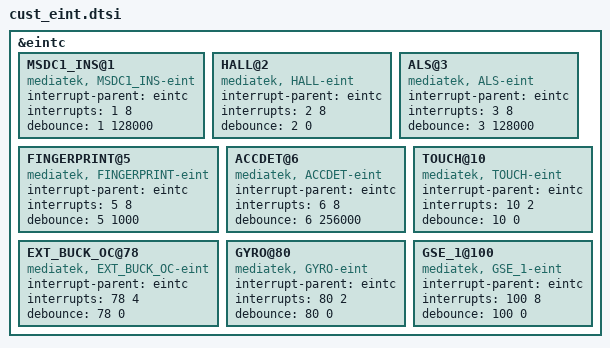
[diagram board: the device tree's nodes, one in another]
/*
 * Generated by MTK SP DrvGen Version 03.13.6 for MT6735M. Copyright MediaTek Inc. (C) 2013.
 * Tue Sep 27 09:54:59 2016
 * Do Not Modify the File.
 */

/*************************
 * EINT DTSI File
*************************/

&eintc {
	MSDC1_INS@1 {
		compatible = "mediatek, MSDC1_INS-eint";
		interrupt-parent = <&eintc>;
		interrupts = <1 8>;
		debounce = <1 128000>;
	};

	HALL@2 {
		compatible = "mediatek, HALL-eint";
		interrupt-parent = <&eintc>;
		interrupts = <2 8>;
		debounce = <2 0>;
	};

	ALS@3 {
		compatible = "mediatek, ALS-eint";
		interrupt-parent = <&eintc>;
		interrupts = <3 8>;
		debounce = <3 128000>;
	};

	FINGERPRINT@5 {
		compatible = "mediatek, FINGERPRINT-eint";
		interrupt-parent = <&eintc>;
		interrupts = <5 8>;
		debounce = <5 1000>;
	};

	ACCDET@6 {
		compatible = "mediatek, ACCDET-eint";
		interrupt-parent = <&eintc>;
		interrupts = <6 8>;
		debounce = <6 256000>;
	};

	TOUCH@10 {
		compatible = "mediatek, TOUCH-eint";
		interrupt-parent = <&eintc>;
		interrupts = <10 2>;
		debounce = <10 0>;
	};

	EXT_BUCK_OC@78 {
		compatible = "mediatek, EXT_BUCK_OC-eint";
		interrupt-parent = <&eintc>;
		interrupts = <78 4>;
		debounce = <78 0>;
	};

	GYRO@80 {
		compatible = "mediatek, GYRO-eint";
		interrupt-parent = <&eintc>;
		interrupts = <80 2>;
		debounce = <80 0>;
	};

	GSE_1@100 {
		compatible = "mediatek, GSE_1-eint";
		interrupt-parent = <&eintc>;
		interrupts = <100 8>;
		debounce = <100 0>;
	};

};
